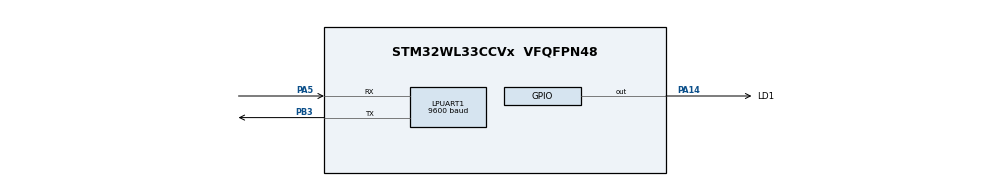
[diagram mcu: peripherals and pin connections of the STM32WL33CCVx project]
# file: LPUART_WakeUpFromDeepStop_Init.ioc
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LPUART1.BaudRate=9600
Mcu.Family=STM32WL3
Mcu.Name=STM32WL33CCVx
Mcu.Package=VFQFPN48
NVIC.LPUART1_IRQn=true\:0\:0\:false\:false\:true\:true\:true\:true
OSCIN.Mode=HSE-External-Oscillator
OSCIN.Signal=RCC_OSC_IN
OSCOUT.Mode=HSE-External-Oscillator
OSCOUT.Signal=RCC_OSC_OUT
PA14.GPIO_FMA14=__NULL
PA14.GPIO_Label=LD1
PA14.Signal=GPIO_Output
PA5.Mode=Asynchronous
PA5.Signal=LPUART1_RX
PB12.Mode=LSE-External-Oscillator
PB12.Signal=RCC_OSC32_OUT
PB13.Mode=LSE-External-Oscillator
PB13.Signal=RCC_OSC32_IN
PB3.Mode=Asynchronous
PB3.Signal=LPUART1_TX
ProjectManager.HeapSize=0x000
ProjectManager.StackSize=0xC00
ProjectManager.TargetToolchain=EWARM V9.30
RCC.ClkSMPSDIVSource=RCC_SMPSCLK_DIV4
RCC.HSE_VALUE=48000000
RCC.HSI_VALUE=64000000
RCC.LPUARTClockSelection=RCC_LPUART1_CLKSOURCE_LSE
RCC.RC64MPLLSource=RCC_LSCOSOURCE_PLL64
VP_PWR_VS_SECSignals.Mode=Security/Privilege
board=custom

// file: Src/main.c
/* USER CODE BEGIN Header */
/**
  ******************************************************************************
  * @file           : main.c
  * @brief          : Main program body
  ******************************************************************************
  * @attention
  *
  * Copyright (c) 2024 STMicroelectronics.
  * All rights reserved.
  *
  * This software is licensed under terms that can be found in the LICENSE file
  * in the root directory of this software component.
  * If no LICENSE file comes with this software, it is provided AS-IS.
  *
  ******************************************************************************
  */
/* USER CODE END Header */
#include "main.h"

/* USER CODE BEGIN PD */
/**
  * @brief Toggle periods for various blinking modes
  */
#define LED_BLINK_FAST  200
#define LED_BLINK_SLOW  500
#define LED_BLINK_ERROR 1000

/* USER CODE END PD */

/* USER CODE BEGIN PM */
#define ATOMIC_SECTION_BEGIN() uint32_t uwPRIMASK_Bit = __get_PRIMASK(); \
                               __disable_irq();
/* Must be called in the same or in a lower scope of ATOMIC_SECTION_BEGIN */
#define ATOMIC_SECTION_END()   __set_PRIMASK(uwPRIMASK_Bit);
/* USER CODE END PM */

/* USER CODE BEGIN PV */
/**
  * @brief Variables used for character reception from PC Com port
  */
__IO uint8_t      ubFinalCharReceived = 0;
__IO uint32_t     ubReceivedChar;

/**
  * @brief Text string printed on PC Com port to inform MCU will enter in Stop 0 Mode
  */
uint8_t aTextInfo[] = "\n\rLPUART Example.\n\rEnter any character.\n\rOn a specific value ('S' or 's'), LD1 is turned On and program ends.\n\rIf different from 'S' or 's', LD1 is turned Off.\n\r";

/* USER CODE END PV */

void SystemClock_Config(void);
void PeriphCommonClock_Config(void);
static void MX_GPIO_Init(void);
static void MX_LPUART1_UART_Init(void);
/* USER CODE BEGIN PFP */
void LED_Init(void);
void LED_On(void);
void LED_Off(void);
void LED_Blinking(uint32_t Period);
void LED_Blinking_3s(void);
void PrintMsg(uint8_t *msg, uint8_t size);
void PrepareLPUARTToStopMode(void);
void EnterDeepStopMode(void);

/* USER CODE END PFP */

int main(void)
{

  /* MCU Configuration--------------------------------------------------------*/

  /* Reset of all peripherals, Initializes the Flash interface and the Systick. */
  LL_APB0_GRP1_EnableClock(LL_APB0_GRP1_PERIPH_SYSCFG);

  /* SysTick_IRQn interrupt configuration */
  NVIC_SetPriority(SysTick_IRQn, 3);

  /* Configure the system clock */
  SystemClock_Config();

  /* Configure the peripherals common clocks */
  PeriphCommonClock_Config();

  /* Initialize all configured peripherals */
  MX_GPIO_Init();
  MX_LPUART1_UART_Init();
  /* USER CODE BEGIN 2 */
  /* Initialize LD1 */
  LED_Init();

  /* Send Text Information on LPUART TX to PC Com port */
  PrintMsg(aTextInfo, sizeof(aTextInfo));
  LED_Blinking_3s();

  /* Start main program loop :
     - Enter Deep Stop mode (LED turned Off)
     - Wait for any character received on LPUART RX line for waking up MCU
     - When a character is received, MCU exits from Deep Stop Mode
     - Make LED blink during 3 sec
     - During this period, all received characters are echoed on the LPUART TX line
     - If a S or a s is received, then program ends and LED is turned on.
     - Otherwise, MCU re-enters Deep Stop mode.
  */
  while (ubFinalCharReceived == 0)
  {
    /* Prepare LPUART for entering Stop Mode */
    PrepareLPUARTToStopMode();

    /* Enter Deep Stop mode */
    EnterDeepStopMode();

    /* At this point, MCU just wakes up from Deep Stop mode */

    /* LD1 blinks during 3 seconds
       During this period, all received characters are echoed on the LPUART TX line
       Send S or s character to end program.
    */
    LED_Blinking_3s();
  }

  /* Turn LD1 On : Expected character has been received */
  LED_On();

  PrintMsg((uint8_t *)"Program end\n\r", 13);
  /* USER CODE END 2 */

  /* Infinite loop */
  while (1)
  {

  }
}

void SystemClock_Config(void)
{
  LL_PWR_SetNoPullB(LL_PWR_GPIO_BIT_12 | LL_PWR_GPIO_BIT_13);
  LL_RCC_LSE_SetDriveCapability(LL_RCC_LSEDRIVE_MEDIUMHIGH);

   /* Enable the LSE */
  LL_RCC_LSE_Enable();

   /* Wait till LSE is ready */
  while(LL_RCC_LSE_IsReady() != 1)
  {
  }

   /* Set HSE Capacitor Tuning */
  LL_RCC_HSE_SetCapacitorTuning(CFG_HW_RCC_HSE_CAPACITOR_TUNE);

   /* Set HSE startup Current */
 LL_RCC_HSE_SetStartupCurrent(0);

   /* Set HSE Amplitude Threshold */
 LL_RCC_HSE_SetAmplitudeThreshold(0);

   /* Set HSE Current Control */
  LL_RCC_HSE_SetCurrentControl(40);

   /* Enable the HSE */
  LL_RCC_HSE_Enable();

   /* Wait till HSE is ready */
  while(LL_RCC_HSE_IsReady() != 1)
  {
  }

  LL_FLASH_SetLatency(LL_FLASH_WAIT_STATES_1);

   /* Enable the RC64MPLL*/
  LL_RCC_RC64MPLL_Enable();

   /* Wait till RC64MPLL is ready */
  while(LL_RCC_RC64MPLL_IsReady() != 1)
  {
  }

  LL_RCC_SetRC64MPLLPrescaler(LL_RCC_RC64MPLL_DIV_1);

   /* Update the SystemCoreClock global variable */
  LL_SetSystemCoreClock(64000000);

   /* Configure the source of time base considering new system clocks settings*/
  LL_Init1msTick(64000000);
}

void PeriphCommonClock_Config(void)
{
  LL_RCC_SetSMPSPrescaler(LL_RCC_SMPS_DIV_4);

   /* Enable the KRM*/
  LL_RCC_KRM_Enable();
  LL_RCC_KRM_SetRateMultiplier(4);
}

static void MX_LPUART1_UART_Init(void)
{

  LL_LPUART_InitTypeDef LPUART_InitStruct = {0};

  LL_GPIO_InitTypeDef GPIO_InitStruct = {0};

  LL_RCC_SetLPUARTClockSource(LL_RCC_LPUCLKSEL_CLKLSE);

  /* Peripheral clock enable */
  LL_APB1_GRP1_EnableClock(LL_APB1_GRP1_PERIPH_LPUART1);

  LL_AHB1_GRP1_EnableClock(LL_AHB1_GRP1_PERIPH_GPIOB);
  LL_AHB1_GRP1_EnableClock(LL_AHB1_GRP1_PERIPH_GPIOA);
  /**LPUART1 GPIO Configuration
  PB3   ------> LPUART1_TX
  PA5   ------> LPUART1_RX
  */
  GPIO_InitStruct.Pin = LL_GPIO_PIN_3;
  GPIO_InitStruct.Mode = LL_GPIO_MODE_ALTERNATE;
  GPIO_InitStruct.Speed = LL_GPIO_SPEED_FREQ_LOW;
  GPIO_InitStruct.OutputType = LL_GPIO_OUTPUT_PUSHPULL;
  GPIO_InitStruct.Pull = LL_GPIO_PULL_NO;
  GPIO_InitStruct.Alternate = LL_GPIO_AF_1;
  LL_GPIO_Init(GPIOB, &GPIO_InitStruct);

  GPIO_InitStruct.Pin = LL_GPIO_PIN_5;
  GPIO_InitStruct.Mode = LL_GPIO_MODE_ALTERNATE;
  GPIO_InitStruct.Speed = LL_GPIO_SPEED_FREQ_LOW;
  GPIO_InitStruct.OutputType = LL_GPIO_OUTPUT_PUSHPULL;
  GPIO_InitStruct.Pull = LL_GPIO_PULL_NO;
  GPIO_InitStruct.Alternate = LL_GPIO_AF_1;
  LL_GPIO_Init(GPIOA, &GPIO_InitStruct);

  /* LPUART1 interrupt Init */
  NVIC_SetPriority(LPUART1_IRQn, 0);
  NVIC_EnableIRQ(LPUART1_IRQn);

  LPUART_InitStruct.PrescalerValue = LL_LPUART_PRESCALER_DIV1;
  LPUART_InitStruct.BaudRate = 9600;
  LPUART_InitStruct.DataWidth = LL_LPUART_DATAWIDTH_8B;
  LPUART_InitStruct.StopBits = LL_LPUART_STOPBITS_1;
  LPUART_InitStruct.Parity = LL_LPUART_PARITY_NONE;
  LPUART_InitStruct.TransferDirection = LL_LPUART_DIRECTION_TX_RX;
  LPUART_InitStruct.HardwareFlowControl = LL_LPUART_HWCONTROL_NONE;
  LL_LPUART_Init(LPUART1, &LPUART_InitStruct);
  LL_LPUART_SetTXFIFOThreshold(LPUART1, LL_LPUART_FIFOTHRESHOLD_1_8);
  LL_LPUART_SetRXFIFOThreshold(LPUART1, LL_LPUART_FIFOTHRESHOLD_1_8);
  LL_LPUART_DisableFIFO(LPUART1);

  LL_LPUART_Enable(LPUART1);

  /* Polling LPUART1 initialisation */
  while((!(LL_LPUART_IsActiveFlag_TEACK(LPUART1))) || (!(LL_LPUART_IsActiveFlag_REACK(LPUART1))))
  {
  }

}

static void MX_GPIO_Init(void)
{
  LL_GPIO_InitTypeDef GPIO_InitStruct = {0};

  /* GPIO Ports Clock Enable */
  LL_AHB1_GRP1_EnableClock(LL_AHB1_GRP1_PERIPH_GPIOB);
  LL_AHB1_GRP1_EnableClock(LL_AHB1_GRP1_PERIPH_GPIOA);

  /**/
  LL_GPIO_ResetOutputPin(LD1_GPIO_Port, LD1_Pin);

  /**/
  GPIO_InitStruct.Pin = LD1_Pin;
  GPIO_InitStruct.Mode = LL_GPIO_MODE_OUTPUT;
  GPIO_InitStruct.Speed = LL_GPIO_SPEED_FREQ_LOW;
  GPIO_InitStruct.OutputType = LL_GPIO_OUTPUT_PUSHPULL;
  GPIO_InitStruct.Pull = LL_GPIO_PULL_NO;
  LL_GPIO_Init(LD1_GPIO_Port, &GPIO_InitStruct);

}

/* USER CODE BEGIN 4 */
/**
  * @brief  Initialize LD1 to Off.
  * @param  None
  * @retval None
  */
void LED_Init(void)
{
  /* Turn LD1 off */
  LL_GPIO_SetOutputPin(LD1_GPIO_Port, LD1_Pin);
}

/**
  * @brief  Turn-on LD1.
  * @param  None
  * @retval None
  */
void LED_On(void)
{
  /* Turn LD1 on */
  LL_GPIO_ResetOutputPin(LD1_GPIO_Port, LD1_Pin);
}

/**
  * @brief  Turn-off LD1.
  * @param  None
  * @retval None
  */
void LED_Off(void)
{
  /* Turn LD1 off */
  LL_GPIO_SetOutputPin(LD1_GPIO_Port, LD1_Pin);
}

/**
  * @brief  Set LD1 to Blinking mode for an infinite loop (toggle period based on value provided as input parameter).
  * @param  Period : Period of time (in ms) between each toggling of LED
  *   This parameter can be user defined values. Pre-defined values used in that example are :
  *     @arg LED_BLINK_FAST : Fast Blinking
  *     @arg LED_BLINK_SLOW : Slow Blinking
  *     @arg LED_BLINK_ERROR : Error specific Blinking
  * @retval None
  */
void LED_Blinking(uint32_t Period)
{
  /* Toggle IO in an infinite loop */
  while (1)
  {
    LL_GPIO_TogglePin(LD1_GPIO_Port, LD1_Pin);
    LL_mDelay(Period);
  }
}

/**
  * @brief  Set LD1 to Blinking mode during 3s.
  * @param  None
  * @retval None
  */
void LED_Blinking_3s(void)
{
  uint32_t index = 0;

  /* Toggle IO in during 3s (15*200ms) */
  for (index = 0; index < 15; index++)
  {
    LL_GPIO_TogglePin(LD1_GPIO_Port, LD1_Pin);
    LL_mDelay(200);
  }
}

/**
  * @brief  Send Txt information message on LPUART Tx line (to PC Com port).
  * @param  msg  Text message to be printed
  * @param  size Size of text message to be printed
  * @retval None
  */
void PrintMsg(uint8_t *msg, uint8_t size)
{
  uint32_t index = 0;

  /* Send characters one per one, until last char to be sent */
  for (index = 0; index < size; index++)
  {
    /* Wait for TXE flag to be raised */
    while (!LL_LPUART_IsActiveFlag_TXE(LPUART1))
    {
    }
    /* Write character in Transmit Data register.
    TXE flag is cleared by writing data in TDR register */
    LL_LPUART_TransmitData8(LPUART1, msg[index]);
  }

  /* Wait for TC flag to be raised for last char */
  while (!LL_LPUART_IsActiveFlag_TC(LPUART1))
  {
  }
}

/**
  * @brief  Function to configure LPUART for being ready to enter "Deep Stop" mode.
  * @param  None
  * @retval None
  */
void PrepareLPUARTToStopMode(void)
{
  /* Empty RX Fifo before entering Stop mode (Otherwise, characters already present in FIFO
     will lead to immediate wake up */
  while (LL_LPUART_IsActiveFlag_RXNE(LPUART1))
  {
    /* Read Received character. RXNE flag is cleared by reading of RDR register */
    ubReceivedChar = LL_LPUART_ReceiveData8(LPUART1);
  }

  /* Clear OverRun Error flag */
  LL_LPUART_ClearFlag_ORE(LPUART1);
  /* Clear Noise Error flag */
  LL_LPUART_ClearFlag_NE(LPUART1);

  /* Make sure that no LPUART transfer is on-going */
  while (LL_LPUART_IsActiveFlag_BUSY(LPUART1) == 1)
  {
  }
  /* Make sure that LPUART is ready to receive */
  while (LL_LPUART_IsActiveFlag_REACK(LPUART1) == 0)
  {
  }

  /* Configure LPUART1 transfer interrupts : */
  LL_LPUART_EnableIT_RXNE(LPUART1);
  /* Enable Wake Up From Stop */
  LL_LPUART_EnableInStopMode(LPUART1);

  /* Specifies the wake up line polarity for the event detection (falling edge) */
  LL_PWR_SetWakeUpPinPolarityLow(LL_PWR_WAKEUP_PORTA, LL_PWR_WAKEUP_PIN5);
}

void EnterDeepStopMode(void)
{
  PrintMsg((uint8_t *)"Enter DEEPSTOP Mode\n\r", 21);

  /* Disable the SysTick */
  LL_SYSTICK_Disable();

  /* About to enter stop mode: switch off LED */
  LED_Off();

  /* Enable wake-up line */
  LL_PWR_ClearWakeupSource(LL_PWR_WAKEUP_PORTA,LL_PWR_WUFA_WUF5);
  LL_PWR_EnableWakeUpPin(LL_PWR_WAKEUP_PORTA, LL_PWR_WAKEUP_PIN5);

  /* Setup the wakeup sources */
  LL_PWR_EnableInternWU(LL_PWR_WAKEUP_LPUART);
  LL_PWR_SetWakeupInternalPolarity(LL_PWR_WAKEUP_LPUART, LL_PWR_WUP_RISIEDG);

  /* Low Power sequence */
  ATOMIC_SECTION_BEGIN();
  PWR_EnterOffMode();
  PWR_ExitOffMode();
  ATOMIC_SECTION_END();

  /* Enable the SysTick */
  LL_SYSTICK_Enable();

  PrintMsg((uint8_t *)"Exit DEEPSTOP Mode\n\r", 20);
}

/******************************************************************************/
/*   IRQ HANDLER TREATMENT Functions                                          */
/******************************************************************************/

/**
  * @brief  Function called from LPUART IRQ Handler when RXNE flag is set
  *         Function is in charge of reading character received on LPUART RX line.
  * @param  None
  * @retval None
  */
void LPUART_CharReception_Callback(void)
{
  /* USER CODE BEGIN Callback 0 */
  /* Read Received character. RXNE flag is cleared by reading of RDR register */
  ubReceivedChar = LL_LPUART_ReceiveData8(LPUART1);

  /* Check if received value is corresponding to specific one : S or s */
  if ((ubReceivedChar == 'S') || (ubReceivedChar == 's'))
  {
    /* End of program : set boolean for main loop exit */
    ubFinalCharReceived = 1;
  }

  /* Echo received character on TX */
  LL_LPUART_TransmitData8(LPUART1, ubReceivedChar);
  /* USER CODE END Callback 0 */

  /* USER CODE BEGIN Callback 1 */

  /* USER CODE END Callback 1 */
}

/**
  * @brief  Function called in case of error detected in LPUART IT Handler
  * @param  None
  * @retval None
  */
void Error_Callback(void)
{
  /* USER CODE BEGIN Callback 0 */

  /* USER CODE END Callback 0 */
  /* Disable LPUART1_IRQn */
  NVIC_DisableIRQ(LPUART1_IRQn);

  /* Unexpected event : Set LED to Blinking mode to indicate error occurs */
  LED_Blinking(LED_BLINK_ERROR);
   /* USER CODE BEGIN Callback 1 */

  /* USER CODE END Callback 1 */
}

/* USER CODE END 4 */

void Error_Handler(void)
{
  __disable_irq();
  while (1)
  {
  }
}
